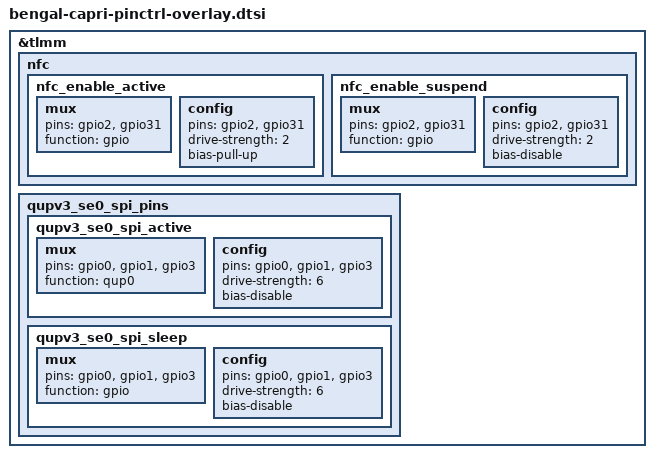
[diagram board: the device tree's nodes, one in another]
&tlmm{
      nfc {
                        nfc_enable_active: nfc_enable_active {
                                /* active state */
                                mux {
                                        /* 2: Enable 31: Firmware */
                                        pins = "gpio2", "gpio31";
                                        function = "gpio";
                                };

                                config {
                                        pins = "gpio2", "gpio31";
                                        drive-strength = <2>; /* 2 MA */
                                        bias-pull-up;
                                };
                        };

                        nfc_enable_suspend: nfc_enable_suspend {
                                /* sleep state */
                                mux {
                                        /* 2: Enable 31: Firmware */
                                        pins = "gpio2", "gpio31";
                                        function = "gpio";
                                };

                                config {
                                        pins = "gpio2", "gpio31";
                                        drive-strength = <2>; /* 2 MA */
                                        bias-disable;
                                };
                        };

       };

       qupv3_se0_spi_pins: qupv3_se0_spi_pins {
                        qupv3_se0_spi_active: qupv3_se0_spi_active {
                                mux {
                                        pins = "gpio0", "gpio1",
                                                        "gpio3";
                                        function = "qup0";
                                };

                                config {
                                        pins = "gpio0", "gpio1",
                                                        "gpio3";
                                        drive-strength = <6>;
                                        bias-disable;
                                };
                        };

                        qupv3_se0_spi_sleep: qupv3_se0_spi_sleep {
                                mux {
                                        pins = "gpio0", "gpio1",
                                                        "gpio3";
                                        function = "gpio";
                                };

                                config {
                                        pins = "gpio0", "gpio1",
                                                        "gpio3";
                                        drive-strength = <6>;
                                        bias-disable;
                                };
                        };
                };

};

